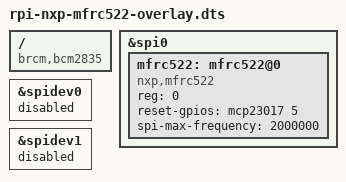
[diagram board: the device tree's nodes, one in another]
/dts-v1/;
/plugin/;

/ {
	compatible = "brcm,bcm2835";

	fragment@0 {
		target = <&spi0>;
		__overlay__ {
			status = "okay";
		};
	};

	fragment@1 {
		target = <&spidev0>;
		__overlay__ {
			status = "disabled";
		};
	};

	fragment@2 {
		target = <&spidev1>;
		__overlay__ {
			status = "disabled";
		};
	};

	fragment@3 {
		target = <&spi0>;
		__overlay__ {
			#address-cells = <1>;
			#size-cells = <0>;

			mfrc522: mfrc522@0 {
				compatible = "nxp,mfrc522";
				reg = <0>;
				reset-gpios = <&mcp23017 5 0>;
				spi-max-frequency = <2000000>;
			};
		};
	};
};
